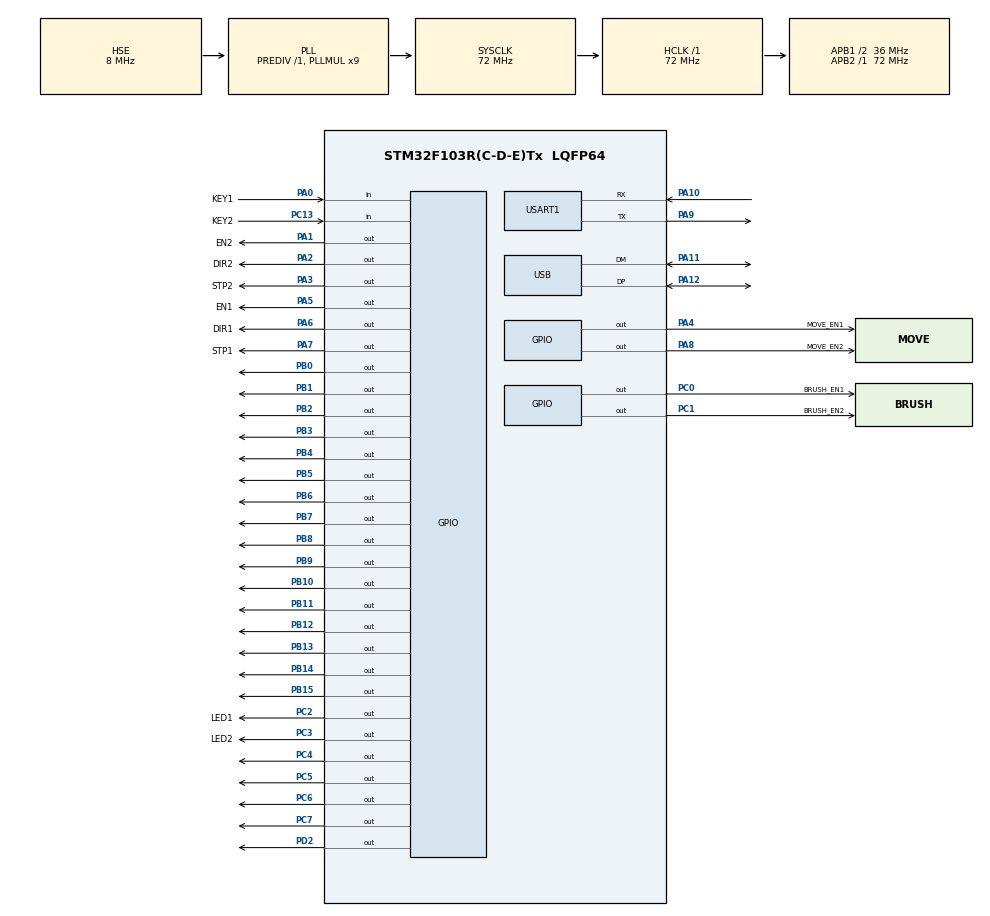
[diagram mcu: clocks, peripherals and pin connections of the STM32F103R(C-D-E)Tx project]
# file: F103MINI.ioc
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Mcu.Family=STM32F1
Mcu.Name=STM32F103R(C-D-E)Tx
Mcu.Package=LQFP64
NVIC.PriorityGroup=NVIC_PRIORITYGROUP_4
NVIC.USB_LP_CAN1_RX0_IRQn=true\:0\:0\:false\:false\:true\:false\:true\:true
PA0-WKUP.GPIO_Label=KEY1
PA0-WKUP.Signal=GPIO_Input
PA1.GPIO_Label=EN2
PA1.Signal=GPIO_Output
PA10.Mode=Asynchronous
PA10.Signal=USART1_RX
PA11.Mode=Device
PA11.Signal=USB_DM
PA12.Mode=Device
PA12.Signal=USB_DP
PA13.Mode=Serial_Wire
PA13.Signal=SYS_JTMS-SWDIO
PA14.Mode=Serial_Wire
PA14.Signal=SYS_JTCK-SWCLK
PA2.GPIO_Label=DIR2
PA2.Signal=GPIO_Output
PA3.GPIO_Label=STP2
PA3.Signal=GPIO_Output
PA4.GPIO_Label=MOVE_EN1
PA4.Signal=GPIO_Output
PA5.GPIO_Label=EN1
PA5.Signal=GPIO_Output
PA6.GPIO_Label=DIR1
PA6.GPIO_PuPd=GPIO_PULLUP
PA6.Signal=GPIO_Output
PA7.GPIO_Label=STP1
PA7.Signal=GPIO_Output
PA8.GPIO_Label=MOVE_EN2
PA8.Signal=GPIO_Output
PA9.Mode=Asynchronous
PA9.Signal=USART1_TX
PB0.Signal=GPIO_Output
PB1.Signal=GPIO_Output
PB10.Signal=GPIO_Output
PB11.Signal=GPIO_Output
PB12.Signal=GPIO_Output
PB13.Signal=GPIO_Output
PB14.Signal=GPIO_Output
PB15.Signal=GPIO_Output
PB2.Signal=GPIO_Output
PB3.Signal=GPIO_Output
PB4.Signal=GPIO_Output
PB5.Signal=GPIO_Output
PB6.Signal=GPIO_Output
PB7.Signal=GPIO_Output
PB8.Signal=GPIO_Output
PB9.Signal=GPIO_Output
PC0.GPIO_Label=BRUSH_EN1
PC0.Signal=GPIO_Output
PC1.GPIO_Label=BRUSH_EN2
PC1.Signal=GPIO_Output
PC13-TAMPER-RTC.GPIO_Label=KEY2
PC13-TAMPER-RTC.Signal=GPIO_Input
PC2.GPIO_Label=LED1
PC2.PinState=GPIO_PIN_SET
PC2.Signal=GPIO_Output
PC3.GPIO_Label=LED2
PC3.PinState=GPIO_PIN_SET
PC3.Signal=GPIO_Output
PC4.Signal=GPIO_Output
PC5.Signal=GPIO_Output
PC6.Signal=GPIO_Output
PC7.Signal=GPIO_Output
PD0-OSC_IN.Mode=HSE-External-Oscillator
PD0-OSC_IN.Signal=RCC_OSC_IN
PD1-OSC_OUT.Mode=HSE-External-Oscillator
PD1-OSC_OUT.Signal=RCC_OSC_OUT
PD2.Signal=GPIO_Output
ProjectManager.HeapSize=0x200
ProjectManager.StackSize=0x1000
ProjectManager.TargetToolchain=Makefile
RCC.AHBFreq_Value=72000000
RCC.APB1CLKDivider=RCC_HCLK_DIV2
RCC.APB1Freq_Value=36000000
RCC.APB1TimFreq_Value=72000000
RCC.APB2Freq_Value=72000000
RCC.APB2TimFreq_Value=72000000
RCC.HCLKFreq_Value=72000000
RCC.PLLMUL=RCC_PLL_MUL9
RCC.PLLSourceVirtual=RCC_PLLSOURCE_HSE
RCC.SYSCLKFreq_VALUE=72000000
RCC.SYSCLKSource=RCC_SYSCLKSOURCE_PLLCLK
RCC.USBFreq_Value=48000000
RCC.USBPrescaler=RCC_USBCLKSOURCE_PLL_DIV1_5
USART1.VirtualMode=VM_ASYNC
USB_DEVICE.CLASS_NAME_FS=CDC
USB_DEVICE.VirtualMode=Cdc
USB_DEVICE.VirtualModeFS=Cdc_FS
VP_USB_DEVICE_VS_USB_DEVICE_CDC_FS.Mode=CDC_FS
board=custom

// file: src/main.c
/* USER CODE BEGIN Header */
/**
  ******************************************************************************
  * @file           : main.c
  * @brief          : Main program body
  ******************************************************************************
  * @attention
  *
  * Copyright (c) 2022 STMicroelectronics.
  * All rights reserved.
  *
  * This software is licensed under terms that can be found in the LICENSE file
  * in the root directory of this software component.
  * If no LICENSE file comes with this software, it is provided AS-IS.
  *
  ******************************************************************************
  */
/* USER CODE END Header */
#include "main.h"
#include "usart.h"
#include "usb_device.h"
#include "gpio.h"

/* USER CODE BEGIN Includes */
#include <stdio.h>
#include "step.h"
/* USER CODE END Includes */

/* USER CODE BEGIN PV */
int key1value = 0;
int key2value = 0;
int dir = 0;
int angel = 0;
int angle_val = 0;
/* USER CODE END PV */

void SystemClock_Config(void);

int main(void)
{
  /* USER CODE BEGIN 1 */
  void SystemClock_Config(void);
  /* USER CODE END 1 */

  /* MCU Configuration--------------------------------------------------------*/

  /* Reset of all peripherals, Initializes the Flash interface and the Systick. */
  HAL_Init();

  /* Configure the system clock */
  SystemClock_Config();

  /* Initialize all configured peripherals */
  MX_GPIO_Init();
  MX_USART1_UART_Init();
  MX_USB_DEVICE_Init();

  /* Infinite loop */
  while (1)
  {

  }
}

void SystemClock_Config(void)
{
  RCC_OscInitTypeDef RCC_OscInitStruct = {0};
  RCC_ClkInitTypeDef RCC_ClkInitStruct = {0};
  RCC_PeriphCLKInitTypeDef PeriphClkInit = {0};

  /** Initializes the RCC Oscillators according to the specified parameters
  * in the RCC_OscInitTypeDef structure.
  */
  RCC_OscInitStruct.OscillatorType = RCC_OSCILLATORTYPE_HSE;
  RCC_OscInitStruct.HSEState = RCC_HSE_ON;
  RCC_OscInitStruct.HSEPredivValue = RCC_HSE_PREDIV_DIV1;
  RCC_OscInitStruct.HSIState = RCC_HSI_ON;
  RCC_OscInitStruct.PLL.PLLState = RCC_PLL_ON;
  RCC_OscInitStruct.PLL.PLLSource = RCC_PLLSOURCE_HSE;
  RCC_OscInitStruct.PLL.PLLMUL = RCC_PLL_MUL9;
  if (HAL_RCC_OscConfig(&RCC_OscInitStruct) != HAL_OK)
  {
    Error_Handler();
  }

  /** Initializes the CPU, AHB and APB buses clocks
  */
  RCC_ClkInitStruct.ClockType = RCC_CLOCKTYPE_HCLK|RCC_CLOCKTYPE_SYSCLK
                              |RCC_CLOCKTYPE_PCLK1|RCC_CLOCKTYPE_PCLK2;
  RCC_ClkInitStruct.SYSCLKSource = RCC_SYSCLKSOURCE_PLLCLK;
  RCC_ClkInitStruct.AHBCLKDivider = RCC_SYSCLK_DIV1;
  RCC_ClkInitStruct.APB1CLKDivider = RCC_HCLK_DIV2;
  RCC_ClkInitStruct.APB2CLKDivider = RCC_HCLK_DIV1;

  if (HAL_RCC_ClockConfig(&RCC_ClkInitStruct, FLASH_LATENCY_2) != HAL_OK)
  {
    Error_Handler();
  }
  PeriphClkInit.PeriphClockSelection = RCC_PERIPHCLK_USB;
  PeriphClkInit.UsbClockSelection = RCC_USBCLKSOURCE_PLL_DIV1_5;
  if (HAL_RCCEx_PeriphCLKConfig(&PeriphClkInit) != HAL_OK)
  {
    Error_Handler();
  }
}

void Error_Handler(void)
{
  __disable_irq();
  while (1)
  {
  }
}
